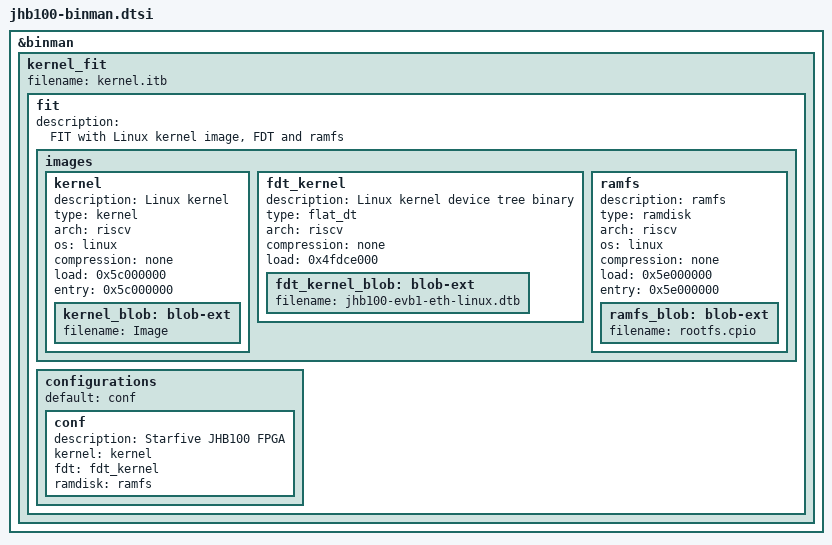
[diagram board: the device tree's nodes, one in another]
// SPDX-License-Identifier: GPL-2.0 OR MIT
/*
 * Copyright (c) 2021-2024 StarFive Technology Co., Ltd.
 */

#include "binman.dtsi"

&binman {
	kernel_fit {
		filename = "kernel.itb";

		fit {
			description = "FIT with Linux kernel image, FDT and ramfs";
			#address-cells = <1>;
			images {
				kernel {
					description = "Linux kernel";
					type = "kernel";
					arch = "riscv";
					os = "linux";
					compression = "none";
					load = /bits/ 64 <0x5c000000>;
					entry = /bits/ 64 <0x5c000000>;
					kernel_blob: blob-ext {
						filename = "Image";
					};
				};
				fdt_kernel {
					description = "Linux kernel device tree binary";
					type = "flat_dt";
					arch = "riscv";
					compression = "none";
					load = /bits/ 64 <0x4fdce000>;
					fdt_kernel_blob: blob-ext {
						filename = "jhb100-evb1-eth-linux.dtb";
					};
				};
				ramfs {
					description = "ramfs";
					type = "ramdisk";
					arch = "riscv";
					os = "linux";
					compression = "none";
					load = /bits/ 64 <0x5e000000>;
					entry = /bits/ 64 <0x5e000000>;
					ramfs_blob: blob-ext {
						filename = "rootfs.cpio";
					};
				};
			};
			configurations {
				default = "conf";
				conf {
					description = "Starfive JHB100 FPGA";
					kernel = "kernel";
					fdt = "fdt_kernel";
					ramdisk = "ramfs";
				};
			};
		};
	};
};
